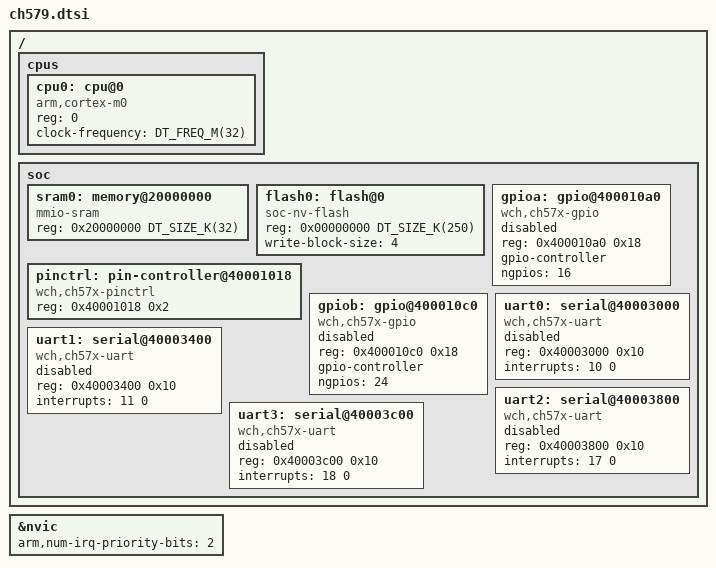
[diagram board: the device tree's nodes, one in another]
/*
 * Copyright The Zephyr Project Contributors
 * SPDX-License-Identifier: Apache-2.0
 */

#include <mem.h>
#include <freq.h>
#include <arm/armv6-m.dtsi>
#include <zephyr/dt-bindings/gpio/gpio.h>
#include <zephyr/dt-bindings/pinctrl/ch57x-pinctrl.h>

/ {
	cpus {
		#address-cells = <1>;
		#size-cells = <0>;

		cpu0: cpu@0 {
			device_type = "cpu";
			compatible = "arm,cortex-m0";
			reg = <0>;
			/* Internal 32 MHz oscillator, set up by soc_early_init_hook() */
			clock-frequency = <DT_FREQ_M(32)>;
		};
	};

	soc {
		sram0: memory@20000000 {
			compatible = "mmio-sram";
			reg = <0x20000000 DT_SIZE_K(32)>;
		};

		flash0: flash@0 {
			compatible = "soc-nv-flash";
			reg = <0x00000000 DT_SIZE_K(250)>;
			write-block-size = <4>;
		};

		pinctrl: pin-controller@40001018 {
			compatible = "wch,ch57x-pinctrl";
			reg = <0x40001018 0x2>;
		};

		gpioa: gpio@400010a0 {
			compatible = "wch,ch57x-gpio";
			reg = <0x400010a0 0x18>;
			gpio-controller;
			#gpio-cells = <2>;
			ngpios = <16>;
			status = "disabled";
		};

		gpiob: gpio@400010c0 {
			compatible = "wch,ch57x-gpio";
			reg = <0x400010c0 0x18>;
			gpio-controller;
			#gpio-cells = <2>;
			ngpios = <24>;
			status = "disabled";
		};

		uart0: serial@40003000 {
			compatible = "wch,ch57x-uart";
			reg = <0x40003000 0x10>;
			interrupts = <10 0>;
			status = "disabled";
		};

		uart1: serial@40003400 {
			compatible = "wch,ch57x-uart";
			reg = <0x40003400 0x10>;
			interrupts = <11 0>;
			status = "disabled";
		};

		uart2: serial@40003800 {
			compatible = "wch,ch57x-uart";
			reg = <0x40003800 0x10>;
			interrupts = <17 0>;
			status = "disabled";
		};

		uart3: serial@40003c00 {
			compatible = "wch,ch57x-uart";
			reg = <0x40003c00 0x10>;
			interrupts = <18 0>;
			status = "disabled";
		};
	};
};

&nvic {
	arm,num-irq-priority-bits = <2>;
};
